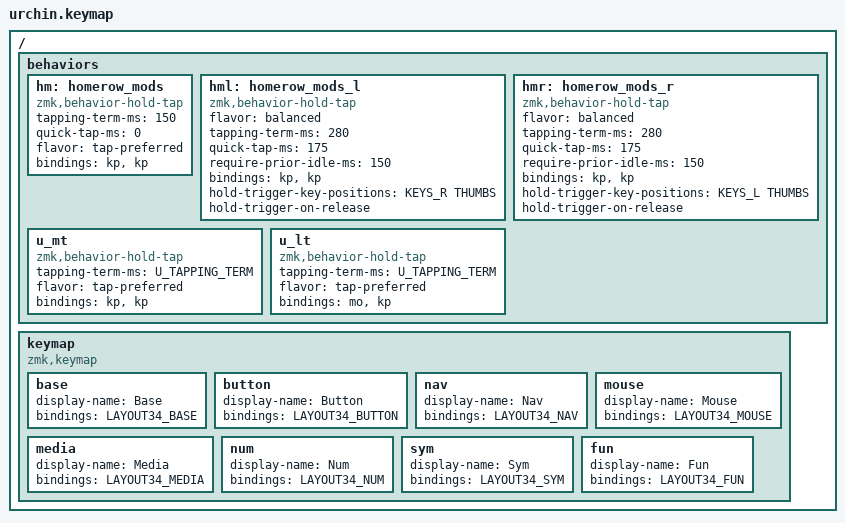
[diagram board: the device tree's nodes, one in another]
#include "34.h"
#include "urchin.h"
#include "layers.h"
#include <dt-bindings/zmk/keys.h>
#include <dt-bindings/zmk/bt.h>
#include <dt-bindings/zmk/rgb.h>
#include <dt-bindings/zmk/outputs.h>
#include <dt-bindings/zmk/ext_power.h>
#include <dt-bindings/zmk/pointing.h>
#include <behaviors.dtsi>
#include <behaviors/mouse_keys.dtsi>

#include "shift_functions.dtsi"

#define MIRYOKU_KLUDGE_THUMBCOMBOS_LEFT 30 31
#define MIRYOKU_KLUDGE_THUMBCOMBOS_RIGHT 32 33

#include "thumbcombos.dtsi"

#define KEYS_L LT0 LT1 LT2 LT3 LT4 LM0 LM1 LM2 LM3 LM4 LB0 LB1 LB2 LB3 LB4  // left-hand keys
#define KEYS_R RT0 RT1 RT2 RT3 RT4 RM0 RM1 RM2 RM3 RM4 RB0 RB1 RB2 RB3 RB4  // right-hand keys
#define THUMBS LH1 LH0 RH0 RH1

/ {
    behaviors {
        hm: homerow_mods {
            compatible = "zmk,behavior-hold-tap";
            #binding-cells = <2>;
            tapping-term-ms = <150>;
            quick-tap-ms = <0>;
            flavor = "tap-preferred";
            bindings = <&kp>, <&kp>;
        };
        hml: homerow_mods_l {
            compatible = "zmk,behavior-hold-tap";
            #binding-cells = <2>;
            flavor = "balanced";
            tapping-term-ms = <280>;
            quick-tap-ms = <175>;
            require-prior-idle-ms = <150>;
            bindings = <&kp>, <&kp>;
            hold-trigger-key-positions = <KEYS_R THUMBS>;
            hold-trigger-on-release;
        };
        hmr: homerow_mods_r {
            compatible = "zmk,behavior-hold-tap";
            #binding-cells = <2>;
            flavor = "balanced";
            tapping-term-ms = <280>;
            quick-tap-ms = <175>;
            require-prior-idle-ms = <150>;
            bindings = <&kp>, <&kp>;
            hold-trigger-key-positions = <KEYS_L THUMBS>;
            hold-trigger-on-release;
        };

        u_mt: u_mt {
          compatible = "zmk,behavior-hold-tap";
          #binding-cells = <2>;
          tapping-term-ms = <U_TAPPING_TERM>;
          flavor = "tap-preferred";
          bindings = <&kp>, <&kp>;
        };
        u_lt: u_lt {
          compatible = "zmk,behavior-hold-tap";
          #binding-cells = <2>;
          tapping-term-ms = <U_TAPPING_TERM>;
          flavor = "tap-preferred";
          bindings = <&mo>, <&kp>;
        };
    };

  keymap {
    compatible = "zmk,keymap";

    base {
      display-name = "Base";
      bindings = < LAYOUT34_BASE >;
    };

    button {
      display-name = "Button";
      bindings = < LAYOUT34_BUTTON>;
    };

    nav {
      display-name = "Nav";
      bindings = < LAYOUT34_NAV >;
    };

    mouse {
      display-name = "Mouse";
      bindings = < LAYOUT34_MOUSE>;
    };

    media {
      display-name = "Media";
      bindings = < LAYOUT34_MEDIA>;
    };

    num {
      display-name = "Num";
      bindings = < LAYOUT34_NUM>;
    };

    sym {
      display-name = "Sym";
      bindings = < LAYOUT34_SYM>;
    };

    fun {
      display-name = "Fun";
      bindings = < LAYOUT34_FUN>;
    };
  };
};

